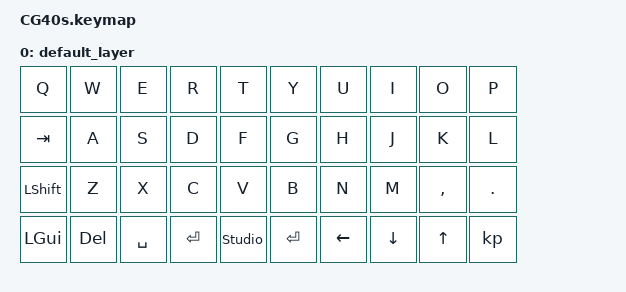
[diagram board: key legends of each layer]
#include <behaviors.dtsi>
#include <dt-bindings/zmk/bt.h>
#include <dt-bindings/zmk/keys.h>
#include <dt-bindings/zmk/keys.h>
#include <dt-bindings/zmk/mouse.h>

/ {
    keymap {
        compatible = "zmk,keymap";

        default_layer {
            bindings = <
               &kp Q       &kp W    &kp E      &kp R    &kp T           &kp Y    &kp U     &kp I     &kp O      &kp P
               &kp TAB     &kp A    &kp S      &kp D    &kp F           &kp G    &kp H     &kp J     &kp K      &kp L
               &kp LSHIFT  &kp Z    &kp X      &kp C    &kp V           &kp B    &kp N     &kp M     &kp COMMA  &kp DOT
               &kp LGUI    &kp DEL  &kp SPACE  &kp RET  &studio_unlock  &kp RET  &kp LEFT  &kp DOWN  &kp UP     &kp 
            >;
        };
    };
};
